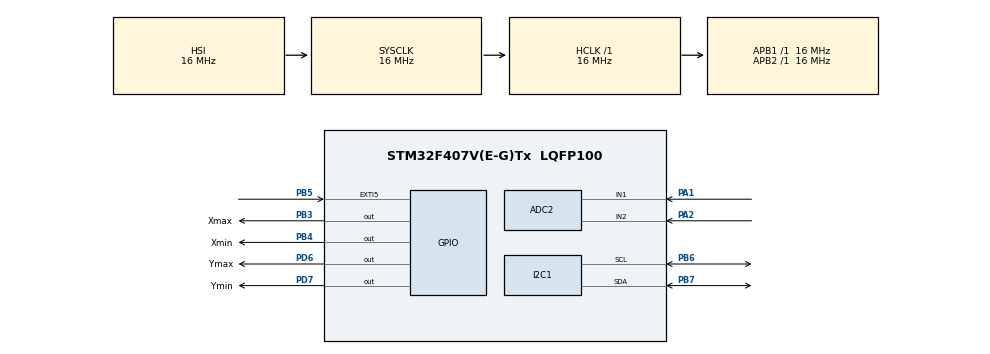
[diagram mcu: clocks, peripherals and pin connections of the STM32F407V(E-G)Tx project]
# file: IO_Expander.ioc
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ADC2.Channel-0\#ChannelRegularConversion=ADC_CHANNEL_1
ADC2.Channel-1\#ChannelRegularConversion=ADC_CHANNEL_2
ADC2.ContinuousConvMode=ENABLE
ADC2.NbrOfConversion=2
ADC2.NbrOfConversionFlag=1
ADC2.Rank-0\#ChannelRegularConversion=1
ADC2.Rank-1\#ChannelRegularConversion=2
ADC2.SamplingTime-0\#ChannelRegularConversion=ADC_SAMPLETIME_144CYCLES
ADC2.SamplingTime-1\#ChannelRegularConversion=ADC_SAMPLETIME_144CYCLES
ADC2.ScanConvMode=ENABLE
Dma.ADC2.0.Direction=DMA_PERIPH_TO_MEMORY
Dma.ADC2.0.FIFOMode=DMA_FIFOMODE_DISABLE
Dma.ADC2.0.Instance=DMA2_Stream2
Dma.ADC2.0.MemDataAlignment=DMA_MDATAALIGN_WORD
Dma.ADC2.0.MemInc=DMA_MINC_ENABLE
Dma.ADC2.0.Mode=DMA_CIRCULAR
Dma.ADC2.0.PeriphDataAlignment=DMA_PDATAALIGN_WORD
Dma.ADC2.0.PeriphInc=DMA_PINC_DISABLE
Dma.ADC2.0.Priority=DMA_PRIORITY_LOW
Dma.Request0=ADC2
FREERTOS.BinarySemaphores01=InputSemaphore,Static,InputSemaphoreControlBlock
FREERTOS.Tasks01=inputTask,24,128,StartInputTask,As weak,NULL,Static,inputTaskBuffer,inputTaskControlBlock
Mcu.Family=STM32F4
Mcu.Name=STM32F407V(E-G)Tx
Mcu.Package=LQFP100
NVIC.DMA2_Stream2_IRQn=true\:5\:0\:false\:false\:true\:true\:false\:true
NVIC.EXTI9_5_IRQn=true\:5\:0\:false\:false\:true\:true\:true\:true
NVIC.I2C1_EV_IRQn=true\:5\:0\:false\:false\:true\:true\:true\:true
NVIC.PriorityGroup=NVIC_PRIORITYGROUP_4
NVIC.TIM2_IRQn=true\:0\:0\:false\:false\:true\:false\:false\:true
NVIC.TimeBase=TIM2_IRQn
NVIC.TimeBaseIP=TIM2
PA1.Signal=ADCx_IN1
PA13.Mode=Serial_Wire
PA13.Signal=SYS_JTMS-SWDIO
PA14.Mode=Serial_Wire
PA14.Signal=SYS_JTCK-SWCLK
PA2.Signal=ADCx_IN2
PB3.GPIO_Label=Xmax
PB3.Signal=GPIO_Output
PB4.GPIO_Label=Xmin
PB4.Signal=GPIO_Output
PB5.GPIO_ModeDefaultEXTI=GPIO_MODE_IT_FALLING
PB5.Signal=GPXTI5
PB6.Mode=I2C
PB6.Signal=I2C1_SCL
PB7.Mode=I2C
PB7.Signal=I2C1_SDA
PD6.GPIO_Label=Ymax
PD6.Signal=GPIO_Output
PD7.GPIO_Label=Ymin
PD7.Signal=GPIO_Output
ProjectManager.HeapSize=0x200
ProjectManager.StackSize=0x400
ProjectManager.TargetToolchain=STM32CubeIDE
RCC.AHBFreq_Value=16000000
RCC.APB1Freq_Value=16000000
RCC.APB2Freq_Value=16000000
RCC.CortexFreq_Value=16000000
RCC.HSE_VALUE=25000000
RCC.HSI_VALUE=16000000
RCC.LSE_VALUE=32768
RCC.SYSCLKFreq_VALUE=16000000
RCC.VCOOutputFreq_Value=192000000
SH.ADCx_IN1.0=ADC2_IN1,IN1
SH.ADCx_IN2.0=ADC2_IN2,IN2
VP_FREERTOS_VS_CMSIS_V2.Mode=CMSIS_V2
VP_SYS_VS_tim2.Mode=TIM2
board=custom

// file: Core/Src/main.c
/* USER CODE BEGIN Header */
/**
 ******************************************************************************
 * @file           : main.c
 * @brief          : Main program body
 ******************************************************************************
 * @attention
 *
 * <h2><center>&copy; Copyright (c) 2020 STMicroelectronics.
 * All rights reserved.</center></h2>
 *
 * This software component is licensed by ST under BSD 3-Clause license,
 * the "License"; You may not use this file except in compliance with the
 * License. You may obtain a copy of the License at:
 *                        opensource.org/licenses/BSD-3-Clause
 *
 ******************************************************************************
 */
/* USER CODE END Header */

#include "main.h"
#include "cmsis_os.h"

typedef StaticTask_t osStaticThreadDef_t;
typedef StaticSemaphore_t osStaticSemaphoreDef_t;

ADC_HandleTypeDef hadc2;
DMA_HandleTypeDef hdma_adc2;

I2C_HandleTypeDef hi2c1;

/* Definitions for inputTask */
osThreadId_t inputTaskHandle;
uint32_t inputTaskBuffer[ 128 ];
osStaticThreadDef_t inputTaskControlBlock;
const osThreadAttr_t inputTask_attributes = {
  .name = "inputTask",
  .stack_mem = &inputTaskBuffer[0],
  .stack_size = sizeof(inputTaskBuffer),
  .cb_mem = &inputTaskControlBlock,
  .cb_size = sizeof(inputTaskControlBlock),
  .priority = (osPriority_t) osPriorityNormal,
};
/* Definitions for InputSemaphore */
osSemaphoreId_t InputSemaphoreHandle;
osStaticSemaphoreDef_t InputSemaphoreControlBlock;
const osSemaphoreAttr_t InputSemaphore_attributes = {
  .name = "InputSemaphore",
  .cb_mem = &InputSemaphoreControlBlock,
  .cb_size = sizeof(InputSemaphoreControlBlock),
};
/* USER CODE BEGIN PV */
static const uint8_t BTN_ADDR = 0x20 << 1;
static const uint8_t REG_BTN = 0x09;
static const uint8_t GPINTEN_ADDR = 0x02;
/* USER CODE END PV */

void SystemClock_Config(void);
static void MX_GPIO_Init(void);
static void MX_DMA_Init(void);
static void MX_ADC2_Init(void);
static void MX_I2C1_Init(void);
void StartInputTask(void *argument);

/* USER CODE BEGIN 0 */
//uint8_t buf;
// unit32_t FR[2];
/* USER CODE END 0 */

int main(void)
{
  /* USER CODE BEGIN 1 */
	HAL_StatusTypeDef ret;
	uint8_t buf;
	int16_t val;

	//uint8_t mask = 1;
  /* USER CODE END 1 */

  /* MCU Configuration--------------------------------------------------------*/

  /* Reset of all peripherals, Initializes the Flash interface and the Systick. */
  HAL_Init();

  /* Configure the system clock */
  SystemClock_Config();

  /* Initialize all configured peripherals */
  MX_GPIO_Init();
  MX_DMA_Init();
  MX_ADC2_Init();
  MX_I2C1_Init();
  /* USER CODE BEGIN 2 */
	//HAL_ADC_Start_DMA(&hadc2, FR, 2);
  /* USER CODE END 2 */
  /* Init scheduler */
  osKernelInitialize();

  /* Create the semaphores(s) */
  /* creation of InputSemaphore */
  InputSemaphoreHandle = osSemaphoreNew(1, 1, &InputSemaphore_attributes);

  /* Create the thread(s) */
  /* creation of inputTask */
  inputTaskHandle = osThreadNew(StartInputTask, NULL, &inputTask_attributes);

  /* Start scheduler */
  osKernelStart();

  /* We should never get here as control is now taken by the scheduler */

  /* Infinite loop */
  while (1)
  {

  }
}

void SystemClock_Config(void)
{
  RCC_OscInitTypeDef RCC_OscInitStruct = {0};
  RCC_ClkInitTypeDef RCC_ClkInitStruct = {0};

  /** Configure the main internal regulator output voltage
  */
  __HAL_RCC_PWR_CLK_ENABLE();
  __HAL_PWR_VOLTAGESCALING_CONFIG(PWR_REGULATOR_VOLTAGE_SCALE1);
  /** Initializes the CPU, AHB and APB busses clocks
  */
  RCC_OscInitStruct.OscillatorType = RCC_OSCILLATORTYPE_HSI;
  RCC_OscInitStruct.HSIState = RCC_HSI_ON;
  RCC_OscInitStruct.HSICalibrationValue = RCC_HSICALIBRATION_DEFAULT;
  RCC_OscInitStruct.PLL.PLLState = RCC_PLL_NONE;
  if (HAL_RCC_OscConfig(&RCC_OscInitStruct) != HAL_OK)
  {
    Error_Handler();
  }
  /** Initializes the CPU, AHB and APB busses clocks
  */
  RCC_ClkInitStruct.ClockType = RCC_CLOCKTYPE_HCLK|RCC_CLOCKTYPE_SYSCLK
                              |RCC_CLOCKTYPE_PCLK1|RCC_CLOCKTYPE_PCLK2;
  RCC_ClkInitStruct.SYSCLKSource = RCC_SYSCLKSOURCE_HSI;
  RCC_ClkInitStruct.AHBCLKDivider = RCC_SYSCLK_DIV1;
  RCC_ClkInitStruct.APB1CLKDivider = RCC_HCLK_DIV1;
  RCC_ClkInitStruct.APB2CLKDivider = RCC_HCLK_DIV1;

  if (HAL_RCC_ClockConfig(&RCC_ClkInitStruct, FLASH_LATENCY_0) != HAL_OK)
  {
    Error_Handler();
  }
}

static void MX_ADC2_Init(void)
{

  ADC_ChannelConfTypeDef sConfig = {0};

  /** Configure the global features of the ADC (Clock, Resolution, Data Alignment and number of conversion)
  */
  hadc2.Instance = ADC2;
  hadc2.Init.ClockPrescaler = ADC_CLOCK_SYNC_PCLK_DIV2;
  hadc2.Init.Resolution = ADC_RESOLUTION_12B;
  hadc2.Init.ScanConvMode = ENABLE;
  hadc2.Init.ContinuousConvMode = ENABLE;
  hadc2.Init.DiscontinuousConvMode = DISABLE;
  hadc2.Init.ExternalTrigConvEdge = ADC_EXTERNALTRIGCONVEDGE_NONE;
  hadc2.Init.ExternalTrigConv = ADC_SOFTWARE_START;
  hadc2.Init.DataAlign = ADC_DATAALIGN_RIGHT;
  hadc2.Init.NbrOfConversion = 2;
  hadc2.Init.DMAContinuousRequests = DISABLE;
  hadc2.Init.EOCSelection = ADC_EOC_SINGLE_CONV;
  if (HAL_ADC_Init(&hadc2) != HAL_OK)
  {
    Error_Handler();
  }
  /** Configure for the selected ADC regular channel its corresponding rank in the sequencer and its sample time.
  */
  sConfig.Channel = ADC_CHANNEL_1;
  sConfig.Rank = 1;
  sConfig.SamplingTime = ADC_SAMPLETIME_144CYCLES;
  if (HAL_ADC_ConfigChannel(&hadc2, &sConfig) != HAL_OK)
  {
    Error_Handler();
  }
  /** Configure for the selected ADC regular channel its corresponding rank in the sequencer and its sample time.
  */
  sConfig.Channel = ADC_CHANNEL_2;
  sConfig.Rank = 2;
  if (HAL_ADC_ConfigChannel(&hadc2, &sConfig) != HAL_OK)
  {
    Error_Handler();
  }

}

static void MX_I2C1_Init(void)
{

  hi2c1.Instance = I2C1;
  hi2c1.Init.ClockSpeed = 100000;
  hi2c1.Init.DutyCycle = I2C_DUTYCYCLE_2;
  hi2c1.Init.OwnAddress1 = 0;
  hi2c1.Init.AddressingMode = I2C_ADDRESSINGMODE_7BIT;
  hi2c1.Init.DualAddressMode = I2C_DUALADDRESS_DISABLE;
  hi2c1.Init.OwnAddress2 = 0;
  hi2c1.Init.GeneralCallMode = I2C_GENERALCALL_DISABLE;
  hi2c1.Init.NoStretchMode = I2C_NOSTRETCH_DISABLE;
  if (HAL_I2C_Init(&hi2c1) != HAL_OK)
  {
    Error_Handler();
  }

}

static void MX_DMA_Init(void)
{

  /* DMA controller clock enable */
  __HAL_RCC_DMA2_CLK_ENABLE();

  /* DMA interrupt init */
  /* DMA2_Stream2_IRQn interrupt configuration */
  HAL_NVIC_SetPriority(DMA2_Stream2_IRQn, 5, 0);
  HAL_NVIC_EnableIRQ(DMA2_Stream2_IRQn);

}

static void MX_GPIO_Init(void)
{
  GPIO_InitTypeDef GPIO_InitStruct = {0};

  /* GPIO Ports Clock Enable */
  __HAL_RCC_GPIOA_CLK_ENABLE();
  __HAL_RCC_GPIOD_CLK_ENABLE();
  __HAL_RCC_GPIOB_CLK_ENABLE();

  /*Configure GPIO pin Output Level */
  HAL_GPIO_WritePin(GPIOD, Ymax_Pin|Ymin_Pin, GPIO_PIN_RESET);

  /*Configure GPIO pin Output Level */
  HAL_GPIO_WritePin(GPIOB, Xmax_Pin|Xmin_Pin, GPIO_PIN_RESET);

  /*Configure GPIO pins : Ymax_Pin Ymin_Pin */
  GPIO_InitStruct.Pin = Ymax_Pin|Ymin_Pin;
  GPIO_InitStruct.Mode = GPIO_MODE_OUTPUT_PP;
  GPIO_InitStruct.Pull = GPIO_NOPULL;
  GPIO_InitStruct.Speed = GPIO_SPEED_FREQ_LOW;
  HAL_GPIO_Init(GPIOD, &GPIO_InitStruct);

  /*Configure GPIO pins : Xmax_Pin Xmin_Pin */
  GPIO_InitStruct.Pin = Xmax_Pin|Xmin_Pin;
  GPIO_InitStruct.Mode = GPIO_MODE_OUTPUT_PP;
  GPIO_InitStruct.Pull = GPIO_NOPULL;
  GPIO_InitStruct.Speed = GPIO_SPEED_FREQ_LOW;
  HAL_GPIO_Init(GPIOB, &GPIO_InitStruct);

  /*Configure GPIO pin : PB5 */
  GPIO_InitStruct.Pin = GPIO_PIN_5;
  GPIO_InitStruct.Mode = GPIO_MODE_IT_FALLING;
  GPIO_InitStruct.Pull = GPIO_NOPULL;
  HAL_GPIO_Init(GPIOB, &GPIO_InitStruct);

  /* EXTI interrupt init*/
  HAL_NVIC_SetPriority(EXTI9_5_IRQn, 5, 0);
  HAL_NVIC_EnableIRQ(EXTI9_5_IRQn);

}

__weak void StartInputTask(void *argument)
{
  for(;;)
  {
    osDelay(1);
  }
}

void HAL_TIM_PeriodElapsedCallback(TIM_HandleTypeDef *htim)
{
  if (htim->Instance == TIM2) {
    HAL_IncTick();
  }
}

void Error_Handler(void)
{
}

/************************ (C) COPYRIGHT STMicroelectronics *****END OF FILE****/
